# S6E1A1 register map
File version: 1.1
Registers are 8-bit, read-write, reset 0x0 unless marked. A register's access mark holds for its fields unless they carry their own. Offsets are from the block's base; [hi:lo] are bit positions; {n}, {i} and the like mark numbered series; 'fields as' and 'values as' point back to an identical list.

## MFT_PPG — PPG Configuration Registers
Base 0x40024000
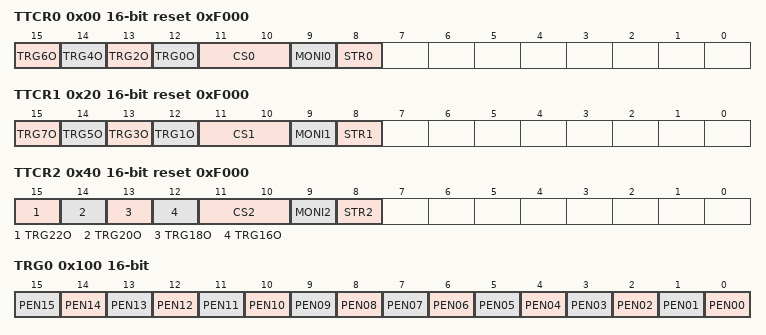
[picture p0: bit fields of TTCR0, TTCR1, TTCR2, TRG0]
0x00 TTCR0 16-bit reset 0xF000 — PPG Start Trigger Control Register 0
  [15] TRG6O wo — PPG6 trigger stop bit
  [14] TRG4O wo — PPG4 trigger stop bit
  [13] TRG2O wo — PPG2 trigger stop bit
  [12] TRG0O wo — PPG0 trigger stop bit
  [11:10] CS0 — 8-bit UP counter clock select bits for comparison
  [9] MONI0 ro — 8-bit UP counter operation state monitor bit for comparison
  [8] STR0 wo — 8-bit UP counter operation enable bit for comparison
0x09 COMP0 — PPG Compare Register 0
0x0C COMP2 — PPG Compare Register 2
0x11 COMP4 — PPG Compare Register 4
0x14 COMP6 — PPG Compare Register 6
0x20 TTCR1 16-bit reset 0xF000 — PPG Start Trigger Control Register 1
  [15] TRG7O wo — PPG7 trigger stop bit
  [14] TRG5O wo — PPG5 trigger stop bit
  [13] TRG3O wo — PPG3 trigger stop bit
  [12] TRG1O wo — PPG1 trigger stop bit
  [11:10] CS1 — 8-bit UP counter clock select bits for comparison
  [9] MONI1 ro — 8-bit UP counter operation state monitor bit for comparison
  [8] STR1 wo — 8-bit UP counter operation enable bit for comparison
0x29 COMP1 — PPG Compare Register 1
0x2C COMP3 — PPG Compare Register 3
0x31 COMP5 — PPG Compare Register 5
0x34 COMP7 — PPG Compare Register 7
0x40 TTCR2 16-bit reset 0xF000 — PPG Start Trigger Control Register 2
  [15] TRG22O wo — PPG22 trigger stop bit
  [14] TRG20O wo — PPG20 trigger stop bit
  [13] TRG18O wo — PPG18 trigger stop bit
  [12] TRG16O wo — PPG16 trigger stop bit
  [11:10] CS2 — 8-bit UP counter clock select bits for comparison
  [9] MONI2 ro — 8-bit UP counter operation state monitor bit for comparison
  [8] STR2 wo — 8-bit UP counter operation enable bit for comparison
0x49 COMP8 — PPG Compare Register 8
0x4C COMP10 — PPG Compare Register 10
0x51 COMP12 — PPG Compare Register 12
0x54 COMP14 — PPG Compare Register 14
0x100 TRG0 16-bit — PPG Start Register 0
  [n] PEN{n:02} (n=0..15) — PPG{n} Start Trigger bit
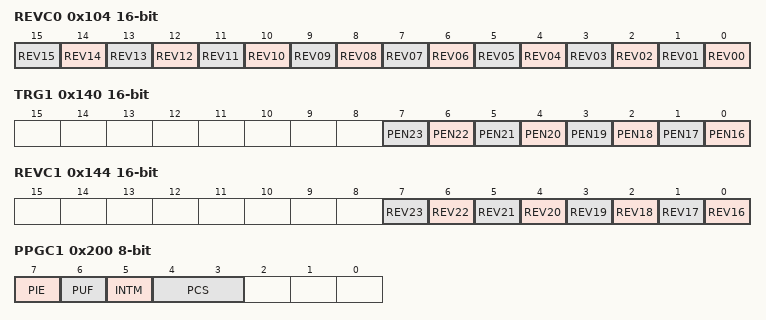
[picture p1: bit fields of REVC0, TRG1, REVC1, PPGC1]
0x104 REVC0 16-bit — ERROR!!!!!!!!!!!!!!!!!!!!
  [n] REV{n:02} (n=0..15) — ERROR!!!!!!!!!!!!!!!!!!!!
0x140 TRG1 16-bit — PPG Start Register 1
  [n-16] PEN{n} (n=16..23) — PPG{n} Start Trigger bit
0x144 REVC1 16-bit — ERROR!!!!!!!!!!!!!!!!!!!!
  [n-16] REV{n} (n=16..23) — ERROR!!!!!!!!!!!!!!!!!!!!
0x200 PPGC1 — ERROR!!!!!!!!!!!!!!!!!!!!
  [7] PIE — ERROR!!!!!!!!!!!!!!!!!!!!
  [6] PUF — ERROR!!!!!!!!!!!!!!!!!!!!
  [5] INTM — ERROR!!!!!!!!!!!!!!!!!!!!
  [4:3] PCS — ERROR!!!!!!!!!!!!!!!!!!!!
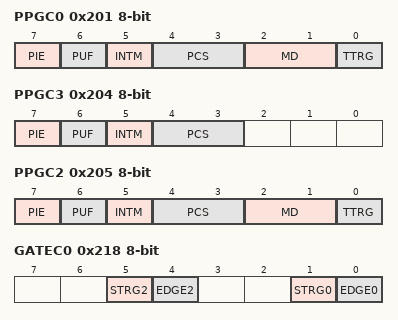
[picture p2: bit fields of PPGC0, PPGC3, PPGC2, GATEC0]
0x201 PPGC0 — ERROR!!!!!!!!!!!!!!!!!!!!
  [7] PIE — ERROR!!!!!!!!!!!!!!!!!!!!
  [6] PUF — ERROR!!!!!!!!!!!!!!!!!!!!
  [5] INTM — ERROR!!!!!!!!!!!!!!!!!!!!
  [4:3] PCS — ERROR!!!!!!!!!!!!!!!!!!!!
  [2:1] MD — ERROR!!!!!!!!!!!!!!!!!!!!
  [0] TTRG — ERROR!!!!!!!!!!!!!!!!!!!!
0x204 PPGC3 — ERROR!!!!!!!!!!!!!!!!!!!!
  fields as PPGC1
0x205 PPGC2 — ERROR!!!!!!!!!!!!!!!!!!!!
  fields as PPGC0
{0x208+4i} PRLL{i} (i=0..3) — ERROR!!!!!!!!!!!!!!!!!!!!
  [7:0] PRLL
{0x209+4i} PRLH{i} (i=0..3) — ERROR!!!!!!!!!!!!!!!!!!!!
  [7:0] PRLH
0x218 GATEC0 — ERROR!!!!!!!!!!!!!!!!!!!!
  [5] STRG2 — ERROR!!!!!!!!!!!!!!!!!!!!
  [4] EDGE2 — ERROR!!!!!!!!!!!!!!!!!!!!
  [1] STRG0 — ERROR!!!!!!!!!!!!!!!!!!!!
  [0] EDGE0 — ERROR!!!!!!!!!!!!!!!!!!!!
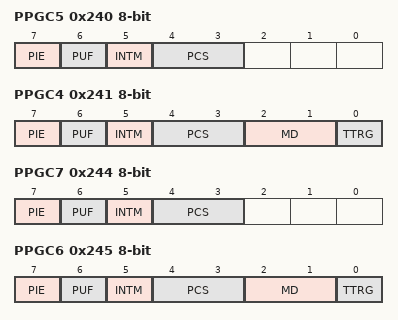
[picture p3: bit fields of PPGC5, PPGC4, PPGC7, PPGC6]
0x240 PPGC5 — ERROR!!!!!!!!!!!!!!!!!!!!
  fields as PPGC1
0x241 PPGC4 — ERROR!!!!!!!!!!!!!!!!!!!!
  fields as PPGC0
0x244 PPGC7 — ERROR!!!!!!!!!!!!!!!!!!!!
  fields as PPGC1
0x245 PPGC6 — ERROR!!!!!!!!!!!!!!!!!!!!
  fields as PPGC0
{0x238+4i} PRLL{i} (i=4..7) — ERROR!!!!!!!!!!!!!!!!!!!!
  [7:0] PRLL
{0x239+4i} PRLH{i} (i=4..7) — ERROR!!!!!!!!!!!!!!!!!!!!
  [7:0] PRLH
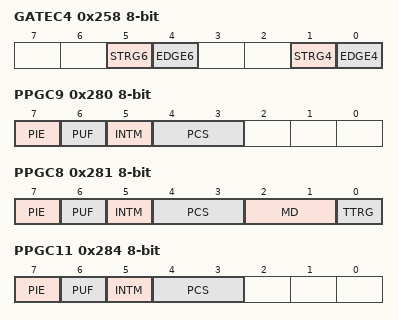
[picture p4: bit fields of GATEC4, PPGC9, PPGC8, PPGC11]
0x258 GATEC4 — ERROR!!!!!!!!!!!!!!!!!!!!
  [5] STRG6 — ERROR!!!!!!!!!!!!!!!!!!!!
  [4] EDGE6 — ERROR!!!!!!!!!!!!!!!!!!!!
  [1] STRG4 — ERROR!!!!!!!!!!!!!!!!!!!!
  [0] EDGE4 — ERROR!!!!!!!!!!!!!!!!!!!!
0x280 PPGC9 — ERROR!!!!!!!!!!!!!!!!!!!!
  fields as PPGC1
0x281 PPGC8 — ERROR!!!!!!!!!!!!!!!!!!!!
  fields as PPGC0
0x284 PPGC11 — ERROR!!!!!!!!!!!!!!!!!!!!
  fields as PPGC1
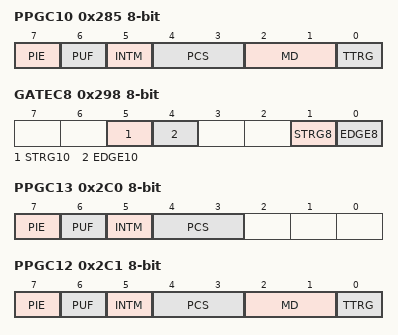
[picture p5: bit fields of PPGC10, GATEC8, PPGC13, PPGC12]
0x285 PPGC10 — ERROR!!!!!!!!!!!!!!!!!!!!
  fields as PPGC0
{0x268+4i} PRLL{i} (i=8..11) — ERROR!!!!!!!!!!!!!!!!!!!!
  [7:0] PRLL
{0x269+4i} PRLH{i} (i=8..11) — ERROR!!!!!!!!!!!!!!!!!!!!
  [7:0] PRLH
0x298 GATEC8 — ERROR!!!!!!!!!!!!!!!!!!!!
  [5] STRG10 — ERROR!!!!!!!!!!!!!!!!!!!!
  [4] EDGE10 — ERROR!!!!!!!!!!!!!!!!!!!!
  [1] STRG8 — ERROR!!!!!!!!!!!!!!!!!!!!
  [0] EDGE8 — ERROR!!!!!!!!!!!!!!!!!!!!
0x2C0 PPGC13 — ERROR!!!!!!!!!!!!!!!!!!!!
  fields as PPGC1
0x2C1 PPGC12 — ERROR!!!!!!!!!!!!!!!!!!!!
  fields as PPGC0
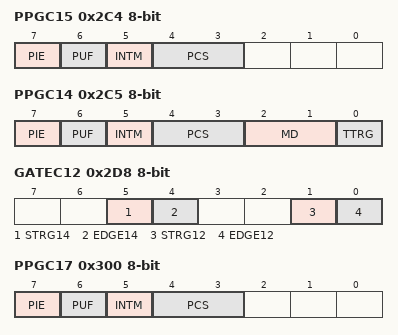
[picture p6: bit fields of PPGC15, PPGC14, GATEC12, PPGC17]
0x2C4 PPGC15 — ERROR!!!!!!!!!!!!!!!!!!!!
  fields as PPGC1
0x2C5 PPGC14 — ERROR!!!!!!!!!!!!!!!!!!!!
  fields as PPGC0
{0x298+4i} PRLL{i} (i=12..15) — ERROR!!!!!!!!!!!!!!!!!!!!
  [7:0] PRLL
{0x299+4i} PRLH{i} (i=12..15) — ERROR!!!!!!!!!!!!!!!!!!!!
  [7:0] PRLH
0x2D8 GATEC12 — ERROR!!!!!!!!!!!!!!!!!!!!
  [5] STRG14 — ERROR!!!!!!!!!!!!!!!!!!!!
  [4] EDGE14 — ERROR!!!!!!!!!!!!!!!!!!!!
  [1] STRG12 — ERROR!!!!!!!!!!!!!!!!!!!!
  [0] EDGE12 — ERROR!!!!!!!!!!!!!!!!!!!!
0x300 PPGC17 — ERROR!!!!!!!!!!!!!!!!!!!!
  fields as PPGC1
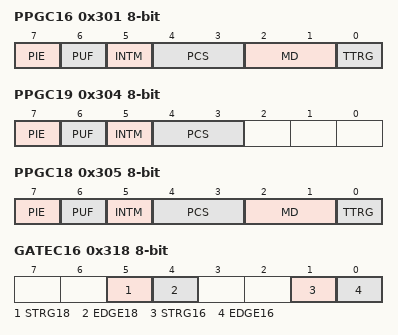
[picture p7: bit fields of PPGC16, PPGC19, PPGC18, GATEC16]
0x301 PPGC16 — ERROR!!!!!!!!!!!!!!!!!!!!
  fields as PPGC0
0x304 PPGC19 — ERROR!!!!!!!!!!!!!!!!!!!!
  fields as PPGC1
0x305 PPGC18 — ERROR!!!!!!!!!!!!!!!!!!!!
  fields as PPGC0
{0x2C8+4i} PRLL{i} (i=16..19) — ERROR!!!!!!!!!!!!!!!!!!!!
  [7:0] PRLL
{0x2C9+4i} PRLH{i} (i=16..19) — ERROR!!!!!!!!!!!!!!!!!!!!
  [7:0] PRLH
0x318 GATEC16 — ERROR!!!!!!!!!!!!!!!!!!!!
  [5] STRG18 — ERROR!!!!!!!!!!!!!!!!!!!!
  [4] EDGE18 — ERROR!!!!!!!!!!!!!!!!!!!!
  [1] STRG16 — ERROR!!!!!!!!!!!!!!!!!!!!
  [0] EDGE16 — ERROR!!!!!!!!!!!!!!!!!!!!
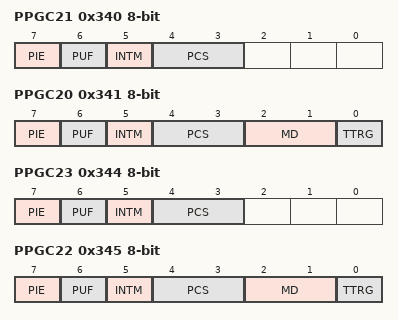
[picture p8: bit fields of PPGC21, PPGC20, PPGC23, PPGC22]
0x340 PPGC21 — ERROR!!!!!!!!!!!!!!!!!!!!
  fields as PPGC1
0x341 PPGC20 — ERROR!!!!!!!!!!!!!!!!!!!!
  fields as PPGC0
0x344 PPGC23 — ERROR!!!!!!!!!!!!!!!!!!!!
  fields as PPGC1
0x345 PPGC22 — ERROR!!!!!!!!!!!!!!!!!!!!
  fields as PPGC0
{0x2F8+4i} PRLL{i} (i=20..23) — ERROR!!!!!!!!!!!!!!!!!!!!
  [7:0] PRLL
{0x2F9+4i} PRLH{i} (i=20..23) — ERROR!!!!!!!!!!!!!!!!!!!!
  [7:0] PRLH
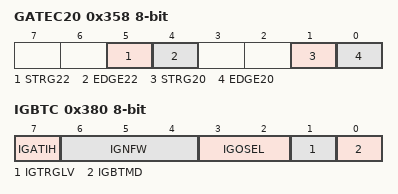
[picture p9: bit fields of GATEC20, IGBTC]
0x358 GATEC20 — ERROR!!!!!!!!!!!!!!!!!!!!
  [5] STRG22 — ERROR!!!!!!!!!!!!!!!!!!!!
  [4] EDGE22 — ERROR!!!!!!!!!!!!!!!!!!!!
  [1] STRG20 — ERROR!!!!!!!!!!!!!!!!!!!!
  [0] EDGE20 — ERROR!!!!!!!!!!!!!!!!!!!!
0x380 IGBTC — ERROR!!!!!!!!!!!!!!!!!!!!
  [7] IGATIH — ERROR!!!!!!!!!!!!!!!!!!!!
  [6:4] IGNFW — ERROR!!!!!!!!!!!!!!!!!!!!
  [3:2] IGOSEL — ERROR!!!!!!!!!!!!!!!!!!!!
  [1] IGTRGLV — ERROR!!!!!!!!!!!!!!!!!!!!
  [0] IGBTMD — ERROR!!!!!!!!!!!!!!!!!!!!
